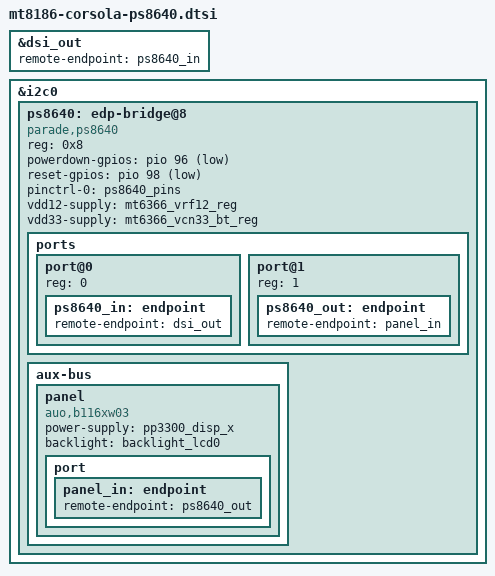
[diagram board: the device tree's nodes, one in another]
// SPDX-License-Identifier: (GPL-2.0 OR MIT)
/*
 * Copyright 2022 Google LLC
 */

&dsi_out {
	remote-endpoint = <&ps8640_in>;
};

&i2c0 {
	/delete-node/anx7625@58;

	ps8640: edp-bridge@8 {
		compatible = "parade,ps8640";
		reg = <0x8>;
		powerdown-gpios = <&pio 96 GPIO_ACTIVE_LOW>;
		reset-gpios = <&pio 98 GPIO_ACTIVE_LOW>;
		pinctrl-names = "default";
		pinctrl-0 = <&ps8640_pins>;
		vdd12-supply = <&mt6366_vrf12_reg>;
		vdd33-supply = <&mt6366_vcn33_bt_reg>;

		ports {
			#address-cells = <1>;
			#size-cells = <0>;

			port@0 {
				reg = <0>;

				ps8640_in: endpoint {
					remote-endpoint = <&dsi_out>;
				};
			};

			port@1 {
				reg = <1>;

				ps8640_out: endpoint {
					remote-endpoint = <&panel_in>;
				};
			};
		};

		aux-bus {
			panel {
				compatible = "auo,b116xw03";
				power-supply = <&pp3300_disp_x>;
				backlight = <&backlight_lcd0>;

				port {
					panel_in: endpoint {
						remote-endpoint = <&ps8640_out>;
					};
				};
			};
		};
	};
};
